# R9A09G057H register map
Vendor: Renesas Electronics; File version: 1.0
Registers are 32-bit, read-write, no defined reset value unless marked. A register's access mark holds for its fields unless they carry their own. Offsets are from the block's base; [hi:lo] are bit positions; {n}, {i} and the like mark numbered series.

## R_INTC — IO define file for intc.
Base 0x10400000
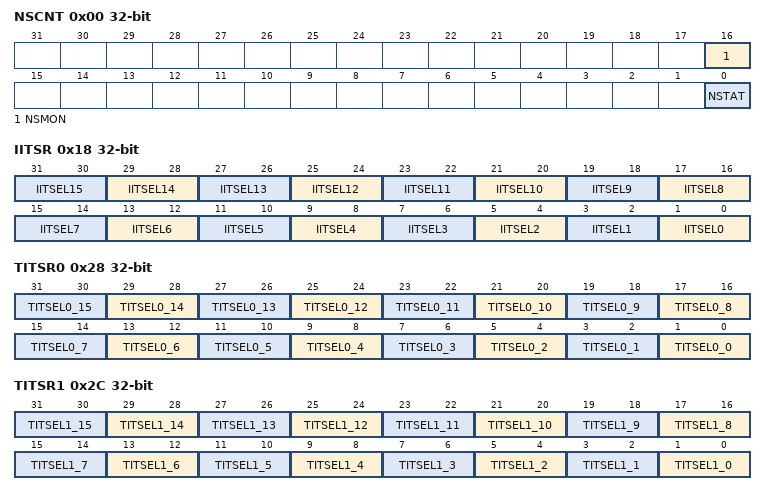
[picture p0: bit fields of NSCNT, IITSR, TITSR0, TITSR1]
0x00 NSCNT ro
  [16] NSMON, [0] NSTAT
0x04 NSCLR
  [0] NCLR wo
0x08 NITSR
  [0] NTSEL
0x10 ISCTR ro
  [15:0] ISTATn
0x14 ISCLR
  [15:0] ICLRn wo
0x18 IITSR
  [2n+1:2n] IITSEL{n} (n=0..15)
0x20 TSCTR ro
  [31:0] TSTATn
0x24 TSCLR wo
  [31:0] TCLRn
0x28 TITSR0
  [2n+1:2n] TITSEL0_{n} (n=0..15)
0x2C TITSR1
  [2n+1:2n] TITSEL1_{n} (n=0..15)
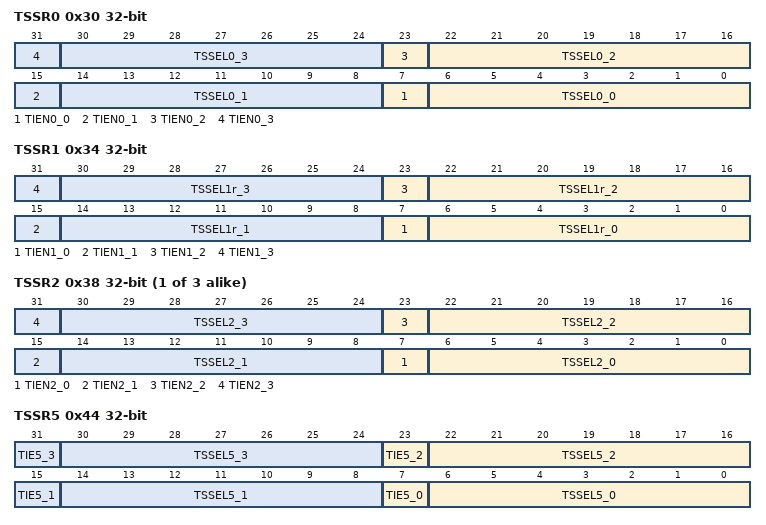
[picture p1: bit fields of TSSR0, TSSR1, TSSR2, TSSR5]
0x30 TSSR0
  [8n+7] TIEN0_{n} (n=0..3), [8n+6:8n] TSSEL0_{n} (n=0..3)
0x34 TSSR1
  [8n+7] TIEN1_{n} (n=0..3), [8n+6:8n] TSSEL1r_{n} (n=0..3)
{0x30+4i} TSSR{i} (i=2..4)
  [8n+7] TIEN{i}_{n} (n=0..3), [8n+6:8n] TSSEL{i}_{n} (n=0..3)
0x44 TSSR5
  [8n+7] TIE5_{n} (n=0..3), [8n+6:8n] TSSEL5_{n} (n=0..3)
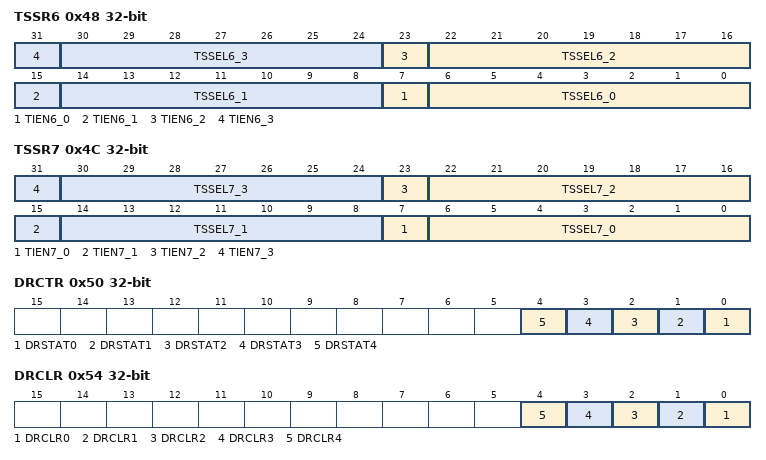
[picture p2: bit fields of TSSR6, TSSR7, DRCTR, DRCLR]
0x48 TSSR6
  [8n+7] TIEN6_{n} (n=0..3), [8n+6:8n] TSSEL6_{n} (n=0..3)
0x4C TSSR7
  [8n+7] TIEN7_{n} (n=0..3), [8n+6:8n] TSSEL7_{n} (n=0..3)
0x50 DRCTR ro
  [n] DRSTAT{n} (n=0..4)
0x54 DRCLR
  [n] DRCLR{n} wo (n=0..4)
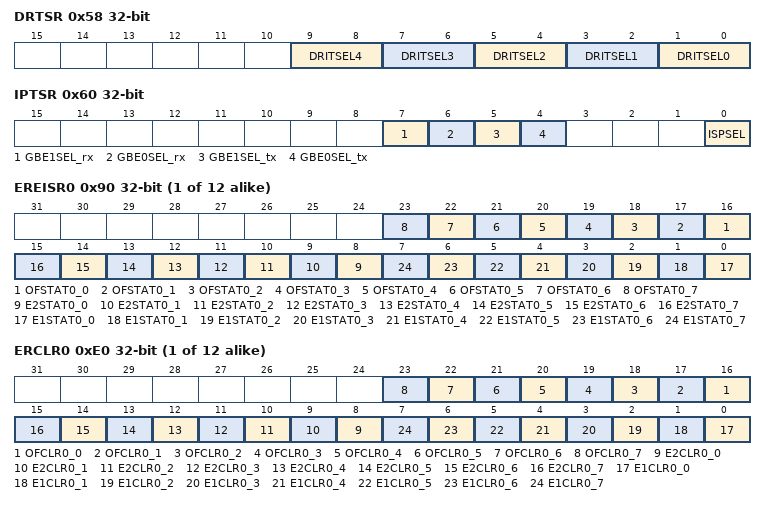
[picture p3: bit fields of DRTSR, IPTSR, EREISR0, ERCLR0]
0x58 DRTSR
  [2n+1:2n] DRITSEL{n} (n=0..4)
0x60 IPTSR
  [7] GBE1SEL_rx, [6] GBE0SEL_rx, [5] GBE1SEL_tx, [4] GBE0SEL_tx, [0] ISPSEL
{0x70+4i} BEISR{i} ro (i=0..3)
  [31:0] BESTAT{i}_n
{0x80+4i} BECLR{i} wo (i=0..3)
  [31:0] BECLR{i}_n
{0x90+4i} EREISR{i} ro (i=0..11)
  [n+16] OFSTAT{i}_{n} (n=0..7), [n+8] E2STAT{i}_{n} (n=0..7), [n] E1STAT{i}_{n} (n=0..7)
{0xE0+4i} ERCLR{i} (i=0..11)
  [n+16] OFCLR{i}_{n} wo (n=0..7), [n+8] E2CLR{i}_{n} wo (n=0..7), [n] E1CLR{i}_{n} wo (n=0..7)
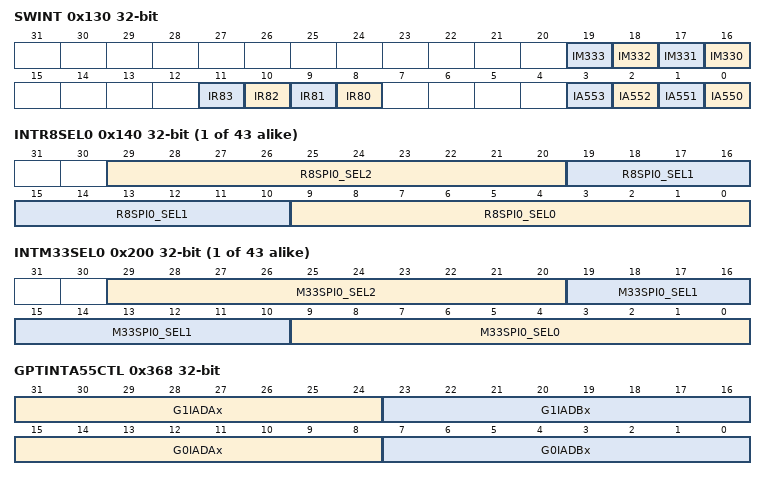
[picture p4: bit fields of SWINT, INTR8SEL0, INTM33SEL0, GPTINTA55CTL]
0x130 SWINT
  [n-314] IM{n} wo (n=330..333), [n-72] IR{n} wo (n=80..83), [n-550] IA{n} wo (n=550..553)
{0x140+4i} INTR8SEL{i} (i=0..42)
  [29:20] R8SPI{i}_SEL2, [19:10] R8SPI{i}_SEL1, [9:0] R8SPI{i}_SEL0
{0x200+4i} INTM33SEL{i} (i=0..42)
  [29:20] M33SPI{i}_SEL2, [19:10] M33SPI{i}_SEL1, [9:0] M33SPI{i}_SEL0
{0x304+4i} ERINTM33CTL{i} ro (i=0..3)
  [31:0] ERRM{i+30}STATn
{0x314+4i} ERINTM33CLR{i} wo (i=0..3)
  [31:0] ERRM{i+30}CLRn
{0x328+4i} ERINTM33MSK{i} (i=0..3)
  [31:0] ERRM{i+30}MKn
{0x338+4i} ERINTA55CTL{i} ro (i=0..3)
  [31:0] ERR{i}STATn
{0x348+4i} ERINTA55CLR{i} wo (i=0..3)
  [31:0] ERRA{i+50}CLRn
{0x358+4i} ERINTA55MSK{i} (i=0..3)
  [31:0] ERRM{i+30}MKn
0x368 GPTINTA55CTL ro
  [31:24] G1IADAx, [23:16] G1IADBx, [15:8] G0IADAx, [7:0] G0IADBx
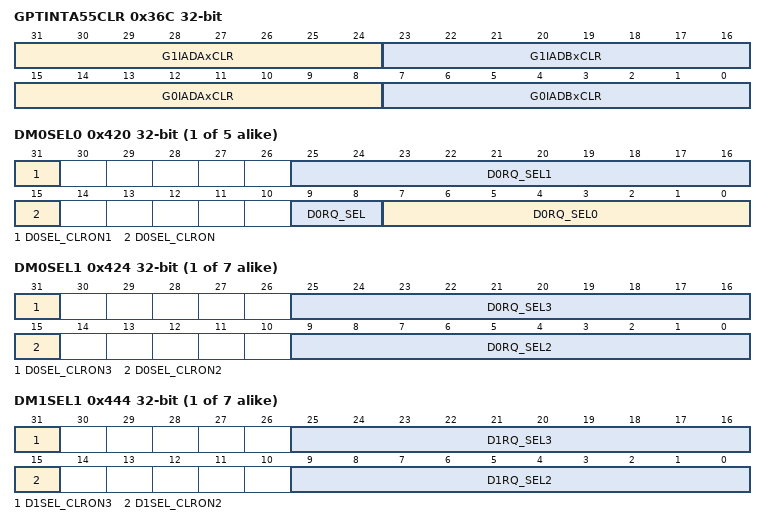
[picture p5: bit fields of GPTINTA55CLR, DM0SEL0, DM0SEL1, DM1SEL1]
0x36C GPTINTA55CLR wo
  [31:24] G1IADAxCLR, [23:16] G1IADBxCLR, [15:8] G0IADAxCLR, [7:0] G0IADBxCLR
0x370 SWPE
  [15:0] PEn wo
{0x400+4i} SWDMAC{i} (i=0..4)
  [15:0] D{i}Cn wo
{0x420+0x20*i} DM{i}SEL0 (i=0..4)
  [31] D{i}SEL_CLRON1, [25:16] D{i}RQ_SEL1, [15] D{i}SEL_CLRON, [9:8] D{i}RQ_SEL, [7:0] D{i}RQ_SEL0
{0x420+4i} DM0SEL{i} (i=1..7)
  [31] D0SEL_CLRON{2i+1}, [25:16] D0RQ_SEL{2i+1}, [15] D0SEL_CLRON{2i}, [9:0] D0RQ_SEL{2i}
{0x440+4i} DM1SEL{i} (i=1..7)
  [31] D1SEL_CLRON{2i+1}, [25:16] D1RQ_SEL{2i+1}, [15] D1SEL_CLRON{2i}, [9:0] D1RQ_SEL{2i}
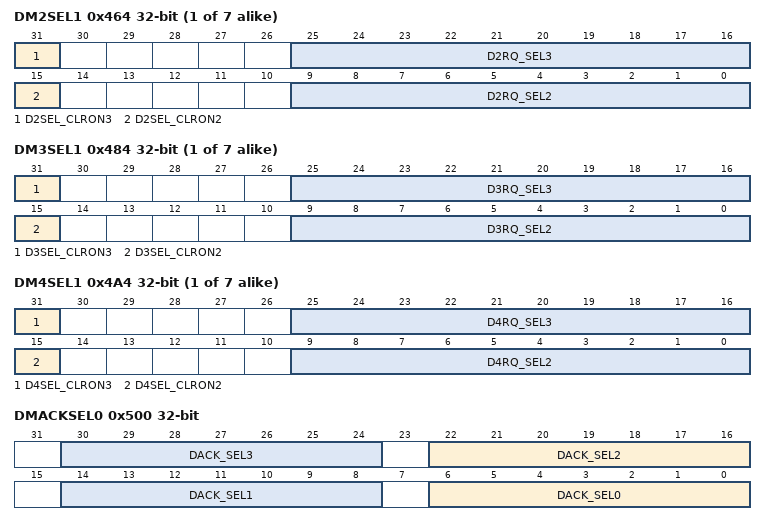
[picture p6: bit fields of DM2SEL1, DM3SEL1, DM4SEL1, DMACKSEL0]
{0x460+4i} DM2SEL{i} (i=1..7)
  [31] D2SEL_CLRON{2i+1}, [25:16] D2RQ_SEL{2i+1}, [15] D2SEL_CLRON{2i}, [9:0] D2RQ_SEL{2i}
{0x480+4i} DM3SEL{i} (i=1..7)
  [31] D3SEL_CLRON{2i+1}, [25:16] D3RQ_SEL{2i+1}, [15] D3SEL_CLRON{2i}, [9:0] D3RQ_SEL{2i}
{0x4A0+4i} DM4SEL{i} (i=1..7)
  [31] D4SEL_CLRON{2i+1}, [25:16] D4RQ_SEL{2i+1}, [15] D4SEL_CLRON{2i}, [9:0] D4RQ_SEL{2i}
{0x4C0+4i} DMRCTR{i} ro (i=0..2)
  [31:0] DMADUP{i}_n
{0x4D0+4i} DMRCLR{i} wo (i=0..2)
  [31:0] DMADUPCLR{i}_n
0x500 DMACKSEL0
  [8n+6:8n] DACK_SEL{n} (n=0..3)
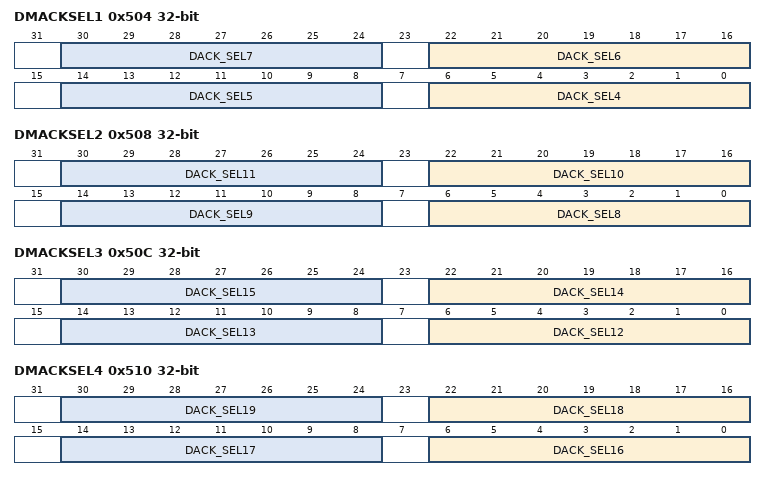
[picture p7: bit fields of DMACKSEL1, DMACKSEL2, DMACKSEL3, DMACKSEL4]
0x504 DMACKSEL1
  [8n-26:8n-32] DACK_SEL{n} (n=4..7)
0x508 DMACKSEL2
  [8n-58:8n-64] DACK_SEL{n} (n=8..11)
0x50C DMACKSEL3
  [8n-90:8n-96] DACK_SEL{n} (n=12..15)
0x510 DMACKSEL4
  [8n-122:8n-128] DACK_SEL{n} (n=16..19)
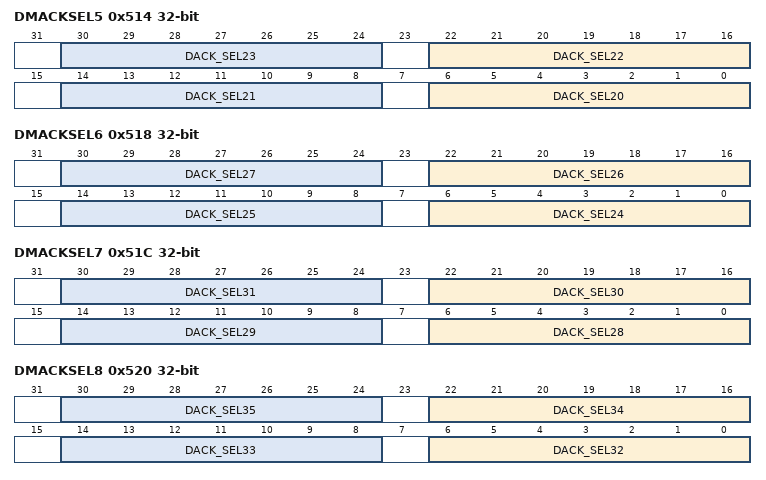
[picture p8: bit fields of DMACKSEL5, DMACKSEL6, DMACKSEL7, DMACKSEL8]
0x514 DMACKSEL5
  [8n-154:8n-160] DACK_SEL{n} (n=20..23)
0x518 DMACKSEL6
  [8n-186:8n-192] DACK_SEL{n} (n=24..27)
0x51C DMACKSEL7
  [8n-218:8n-224] DACK_SEL{n} (n=28..31)
0x520 DMACKSEL8
  [8n-250:8n-256] DACK_SEL{n} (n=32..35)
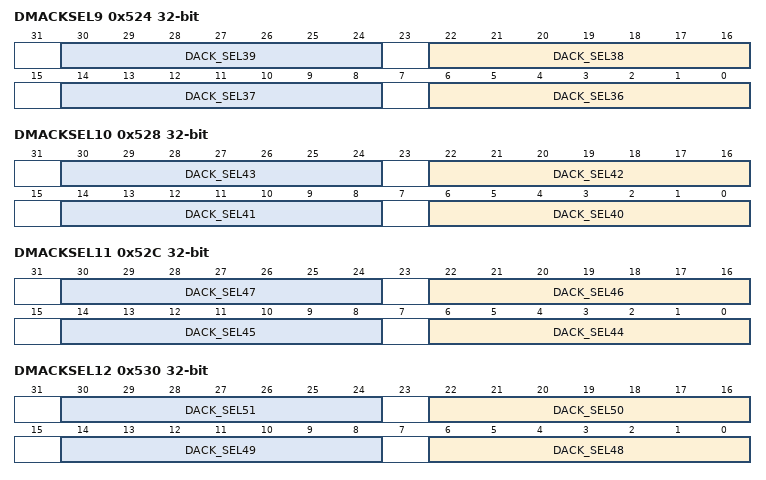
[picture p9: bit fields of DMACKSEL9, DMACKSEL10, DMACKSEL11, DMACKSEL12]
0x524 DMACKSEL9
  [8n-282:8n-288] DACK_SEL{n} (n=36..39)
0x528 DMACKSEL10
  [8n-314:8n-320] DACK_SEL{n} (n=40..43)
0x52C DMACKSEL11
  [8n-346:8n-352] DACK_SEL{n} (n=44..47)
0x530 DMACKSEL12
  [8n-378:8n-384] DACK_SEL{n} (n=48..51)
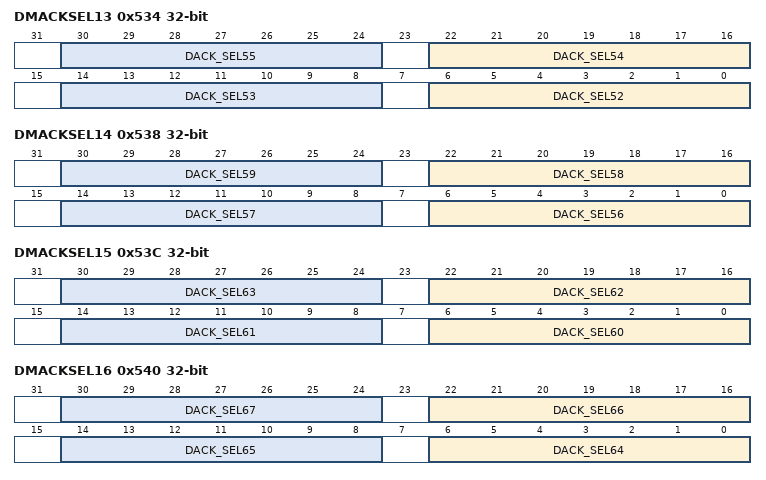
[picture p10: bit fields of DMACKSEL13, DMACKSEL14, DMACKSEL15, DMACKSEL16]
0x534 DMACKSEL13
  [8n-410:8n-416] DACK_SEL{n} (n=52..55)
0x538 DMACKSEL14
  [8n-442:8n-448] DACK_SEL{n} (n=56..59)
0x53C DMACKSEL15
  [8n-474:8n-480] DACK_SEL{n} (n=60..63)
0x540 DMACKSEL16
  [8n-506:8n-512] DACK_SEL{n} (n=64..67)
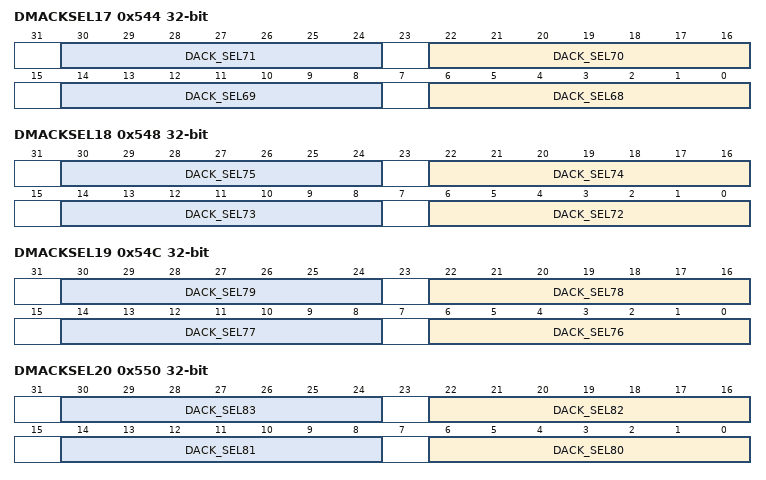
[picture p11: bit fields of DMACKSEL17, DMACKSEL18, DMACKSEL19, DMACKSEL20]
0x544 DMACKSEL17
  [8n-538:8n-544] DACK_SEL{n} (n=68..71)
0x548 DMACKSEL18
  [8n-570:8n-576] DACK_SEL{n} (n=72..75)
0x54C DMACKSEL19
  [8n-602:8n-608] DACK_SEL{n} (n=76..79)
0x550 DMACKSEL20
  [8n-634:8n-640] DACK_SEL{n} (n=80..83)
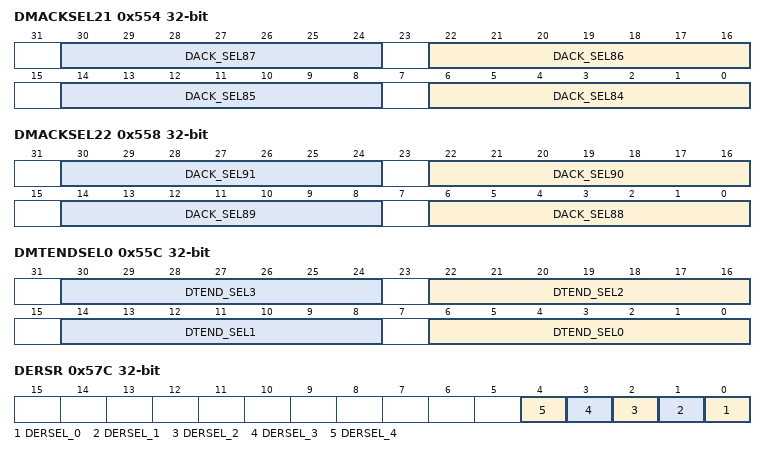
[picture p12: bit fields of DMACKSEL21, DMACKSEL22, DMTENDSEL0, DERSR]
0x554 DMACKSEL21
  [8n-666:8n-672] DACK_SEL{n} (n=84..87)
0x558 DMACKSEL22
  [8n-698:8n-704] DACK_SEL{n} (n=88..91)
0x55C DMTENDSEL0
  [8n+6:8n] DTEND_SEL{n} (n=0..3)
0x560 DMTENDSEL1
  [6:0] DTEND_SEL4
{0x570+4i} DMESR{i} (i=0..2)
  [31:0] DMESEL{i}_n
0x57C DERSR
  [n] DERSEL_{n} (n=0..4)
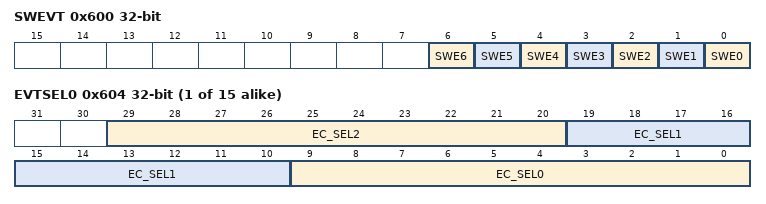
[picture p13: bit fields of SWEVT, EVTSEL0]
0x600 SWEVT
  [n] SWE{n} (n=0..6)
{0x604+4i} EVTSEL{i} (i=0..14)
  [29:20] EC_SEL{3i+2}, [19:10] EC_SEL{3i+1}, [9:0] EC_SEL{3i}
{0x780+4i} OFFDMSTAT{i} ro (i=0..2)
  [31:0] OD{i}STATn
{0x798+4i} OFFDMCLR{i} wo (i=0..2)
  [31:0] ODCLR{i}
